# gcr_me14 register map
Registers are access not given, no defined reset value unless marked. A register's access mark holds for its fields unless they carry their own. Offsets are from the block's base; lines under a group give offsets from that group; [hi:lo] are bit positions; {n}, {i} and the like mark numbered series; 'fields as' and 'values as' point back to an identical list; <NAME> marks a mode.

## Memory map
0x40000000 GCR size 0x400 — Global Control Registers.

## GCR — Global Control Registers.
Base 0x40000000
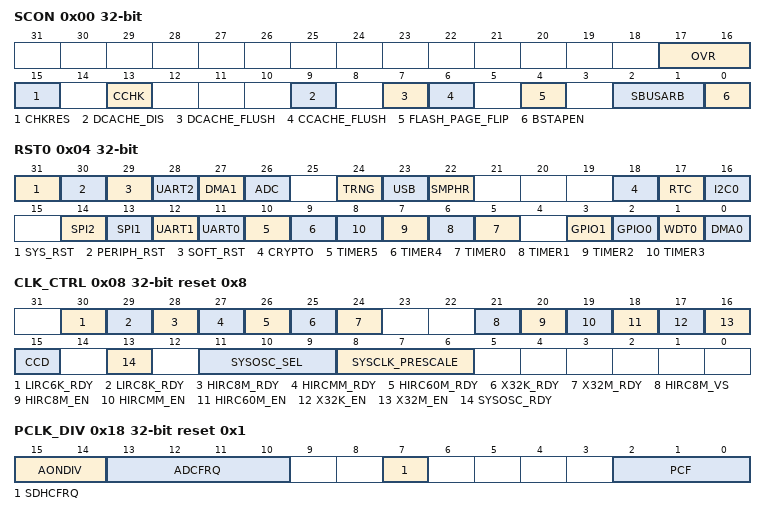
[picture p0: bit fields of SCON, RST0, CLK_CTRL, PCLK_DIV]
0x00 SCON — System Control.
  [17:16] OVR — Operating Voltage Range. Setting these bits according to the VCore voltage allows the on-chip Random-Access memories to operate in their optimal timing range.
    0=0_9V (0.9V +/- 10%); 1=1_0V (1.0V +/- 10%); 2=1_1V (1.1V +/- 10%)
  [15] CHKRES — ROM Checksum Result. This bit is only valid when CHKRD=1.
    0=pass (ROM Checksum Correct.); 1=fail (ROM Checksum Fail.)
  [13] CCHK — Compute ROM Checksum. This bit is self-cleared when calculation is completed. Once set, software clearing this bit is ignored and the bit will remain set until the operation is completed.
    0=complete (No operation/complete.); 1=Start operation
  [9] DCACHE_DIS — Data Cache Disable. The system cache(s) will be completely disabled when this bit is set.
    0=en (Is enabled.); 1=dis (Is Disabled.)
  [7] DCACHE_FLUSH — Data Cache Flush. The system cache(s) will be flushed when this bit is set.
    0=Normal System Cache Operation; 1=flush (System Cache is flushed)
  [6] CCACHE_FLUSH — Code Cache Flush. This bit is used to flush the code caches and the instruction buffer of the Cortex-M4.
    0=Normal Code Cache Operation; 1=flush (Code Caches and CPU instruction buffer are flushed)
  [4] FLASH_PAGE_FLIP — Flips the Flash bottom and top halves. (Depending on the total flash size, each half is either 256K or 512K). Initiating a flash page flip will cause a flush of both the data buffer on the DCODE bus and the internal instruction buffer.
    0=normal (Physical layout matches logical layout.); 1=swapped (Bottom half mapped to logical top half and vice versa.)
  [2:1] SBUSARB — System bus abritration scheme. These bits are used to select between Fixed-burst abritration and Round-Robin scheme. The Round-Robin scheme is selected by default. These bits are reset by the system reset.
    0=fix (Fixed Burst abritration.); 1=Round-robin scheme
  [0] BSTAPEN — Boundary Scan TAP enable. When enabled, the JTAG port is connected to the Boundary Scan TAP. Otherwise, the port is connected to the ARM ICE function. This bit is reset by the POR. Reset value and access depend on the part number.
    0=dis (Boundary Scan TAP port disabled.); 1=en (Boundary Scan TAP port enabled.)
0x04 RST0 — Reset.
  [31] SYS_RST — System Reset. Setting this bit to 1 resets the CPU core and all peripherals, including the watchdog timer.
  [30] PERIPH_RST — Peripheral Reset. Setting this bit to 1 resets all peripherals. The CPU core, the watchdog timer, and all GPIO pins are unaffected by this reset.
  [29] SOFT_RST — Soft Reset. Setting this bit to 1 resets everything except the CPU and the watchdog timer.
  [28] UART2 — UART2 Reset. Setting this bit to 1 resets all UART 2 blocks.
  [27] DMA1 — DMA 1 Reset.
  [26] ADC — Analog to Digital Reset.
  [24] TRNG — TRNG Reset.
  [23] USB — USB Reset. Setting this bit resets both USB blocks.
  [22] SMPHR — SMPHR Reset. Setting this bit to 1 resets the SMPHR block.
  [18] CRYPTO — Cryptographic Reset. Setting this bit to 1 resets the AES block, the SHA block and the DES block.
  [17] RTC — Real Time Clock Reset.
  [16] I2C0 — I2C0 Reset.
  [14] SPI2 — SPI2 Reset. Setting this bit to 1 resets all SPI 2 blocks.
  [13] SPI1 — SPI1 Reset. Setting this bit to 1 resets all SPI 1 blocks.
  [12] UART1 — UART1 Reset. Setting this bit to 1 resets all UART 1 blocks.
  [11] UART0 — UART0 Reset. Setting this bit to 1 resets all UART 0 blocks.
  [10] TIMER5 — Timer3 Reset. Setting this bit to 1 resets Timer 5 blocks.
  [9] TIMER4 — Timer3 Reset. Setting this bit to 1 resets Timer 4 blocks.
  [n+5] TIMER{n} (n=0..3) — Timer{n} Reset. Setting this bit to 1 resets Timer {n} blocks.
  [3] GPIO1 — GPIO1 Reset. Setting this bit to 1 resets GPIO1 pins to their default states.
  [2] GPIO0 — GPIO0 Reset. Setting this bit to 1 resets GPIO0 pins to their default states.
  [1] WDT0 — Watchdog Timer Reset.
  [0] DMA0 — DMA Reset.
    0=reset_done (Reset complete.); 1=busy (Starts Reset or indicates reset in progress.)
0x08 CLK_CTRL reset 0x8 — Clock Control.
  [30] LIRC6K_RDY ro — 6kHz Low Frequency Reference Clock Ready.
    0=not (Is not Ready.); 1=ready (Is Ready.)
  [29] LIRC8K_RDY ro — 8kHz Low Frequency Reference Clock Ready.
    0=not (Is not Ready.); 1=ready (Is Ready.)
  [28] HIRC8M_RDY ro — 8MHz HIRC Ready.
    0=not (Is not Ready.); 1=ready (Is Ready.)
  [27] HIRCMM_RDY ro — 96MHz HIRC Ready.
    0=not (Is not Ready.); 1=ready (Is Ready.)
  [26] HIRC60M_RDY ro — 60MHz HIRC Ready.
    0=not (Is not Ready.); 1=ready (Is Ready.)
  [25] X32K_RDY ro — 32kHz Crystal Oscillator Ready
    0=not (Is not Ready.); 1=ready (Is Ready.)
  [24] X32M_RDY ro — 32MHz Crystal Oscillator Ready
    0=not (Is not Ready.); 1=ready (Is Ready.)
  [21] HIRC8M_VS — 8MHz High Frequency Internal Reference Clock Voltage Select. This register bit is used to select the power supply to the HIRC8M.
    0=VCore Supply; 1=1V (Dedicated 1v regulated supply.)
  [20] HIRC8M_EN — 8MHz High Frequency Internal Reference Clock Enable.
    0=dis (Is Disabled.); 1=en (Is Enabled.)
  [19] HIRCMM_EN — 96MHz High Frequency Internal Reference Clock Enable.
    0=dis (Is Disabled.); 1=en (Is Enabled.)
  [18] HIRC60M_EN — 60MHz High Frequency Internal Reference Clock Enable.
    0=dis (Is Disabled.); 1=en (Is Enabled.)
  [17] X32K_EN — 32kHz Crystal Oscillator Enable.
    0=dis (Is Disabled.); 1=en (Is Enabled.)
  [16] X32M_EN — 32MHz Crystal Oscillator Enable.
    0=dis (Is Disabled.); 1=en (Is Enabled.)
  [15] CCD ro — Cryptographic clock divider
    0=non_div (The cryptographic accelerator clock is running in non-divided mode.); 1=div (The cryptographic accelerator clock is running in divided mode.)
  [13] SYSOSC_RDY ro — Clock Ready. This read only bit reflects whether the currently selected system clock source is running.
    0=busy (Switchover to the new clock source (as selected by CLKSEL) has not yet occurred.); 1=ready (System clock running from CLKSEL clock source.)
  [11:9] SYSOSC_SEL — Clock Source Select. This 3 bit field selects the source for the system clock.
    0=HIRC (HIRC Clock); 2=XTAL32M (32MHz Crystal is used for the system clock.); 3=LIRC8 (8kHz LIRC is used for the system clock.); 4=HIRC96 (The internal 96 MHz oscillator is used for the system clock.); 5=HIRC8 (The internal 8 MHz oscillator is used for the system clock.); 6=XTAL32k (32kHz is used for the system clock.)
  [8:6] SYSCLK_PRESCALE — Prescaler Select. This 3 bit field sets the system operating frequency by controlling the prescaler that divides the output of the PLL0.
    0=div1 (Divide by 1.); 1=div2 (Divide by 2.); 2=div4 (Divide by 4.); 3=div8 (Divide by 8.); 4=div16 (Divide by 16.); 5=div32 (Divide by 32.); 6=div64 (Divide by 64.); 7=div128 (Divide by 128.)
0x0C PMR — Power Management.
  [20] XTALPB — 32MHz Bluetooth Oscillator Bypass.
  [17] HIRC8MPD — 8MHz power down. This bit selects 8MHz HIRC power state in DEEPSLEEP mode.
    0=active (Mode is Active.); 1=deepsleep (Powered down in DEEPSLEEP.)
  [16] HIRC96MPD — 96MHz power down. This bit selects 96MHz HIRC power state in DEEPSLEEP mode.
    values as HIRC8MPD
  [15] HIRCPD — HIRC Power Down. This bit selects HIRC power state in DEEPSLEEP mode.
    values as HIRC8MPD
  [8] SDMAWKEN — SDMA Wake Up Enable. This bit enables SDMA IRQ activity as wakeup source.
    0=dis (Wake Up Disable.); 1=en (Wake Up Enable.)
  [8] compwken — COMPARATOR Input Wake Up Enable. This bit enables COMP IRQ activity as wakeup source.
    0=dis (Wake Up Disable.); 1=en (Wake Up Enable.)
  [7] WUTWKEN — WUT Wake Up Enable. This bit enables WUT IRQ as wakeup source.
    0=dis (Wake Up Disable.); 1=en (Wake Up Enable.)
  [6] USBWKEN — USB Wake Up Enable. This bit enables USB activity as wakeup source.
    0=dis (Wake Up Disable.); 1=en (Wake Up Enable.)
  [5] RTCWKEN — RTC Alarm Wake Up Enable. This bit enables RTC alarm as wakeup source. If enabled, the desired RTC alarm must be configured via the RTC control registers.
    0=dis (Wake Up Disable.); 1=en (Wake Up Enable.)
  [4] GPIOWKEN — GPIO Wake Up Enable. This bit enables all GPIO pins as potential wakeup sources. Any GPIO configured for wakeup is capable of causing an exit from IDLE or STANDBY modes when this bit is set.
    0=dis (Wake Up Disable.); 1=en (Wake Up Enable.)
  [2:0] MODE — Operating Mode. This two bit field selects the current operating mode for the device. Note that code execution only occurs during ACTIVE mode.
    0=Active Mode; 2=DeepSleep Mode; 3=Shutdown Mode; 4=Backup Mode
0x18 PCLK_DIV reset 0x1 — Peripheral Clock Divider.
  [15:14] AONDIV — Always-ON(AON) domain CLock Divider. These bits define the AON domain clock divider.
    0=div_4 (PCLK divide by 4.); 1=div_8 (PCLK divide by 8.); 2=div_16 (PCLK divide by 16.); 3=div_32 (PCLK divide by 32.)
  [13:10] ADCFRQ — ADC clock Frequency. These bits define the ADC clock frequency. FADC = FPCLK/(ADCFRQ).
  [7] SDHCFRQ — SDHC Clock Frequency. This bits defines the clock frequency of SDHC.
    0=48MHz; 1=24MHz
  [2:0] PCF — These bits determine the clock frequency for the UART, I2C and Key Pad peripherals. These peripherals have an adaptive clock generator that dynamically adjusts the peripheral frequency based on the main system bus frequency. These bits are dynamically updated when the PLL0 is selected as the system clock source and are set by hardware. These bits determine the clock frequency for the UART, I2C and Key Pad peripherals. These peripherals have an adaptive clock generator that dynamically adjusts the peripheral frequency based on the main system bus frequency. These bits are dynamically updated when the PLL0 is selected as the system clock source and are set by hardware.
    2=96MHz; 3=48MHz; 4=24MHz; 5=12MHz; 6=6MHz; 7=3MHz
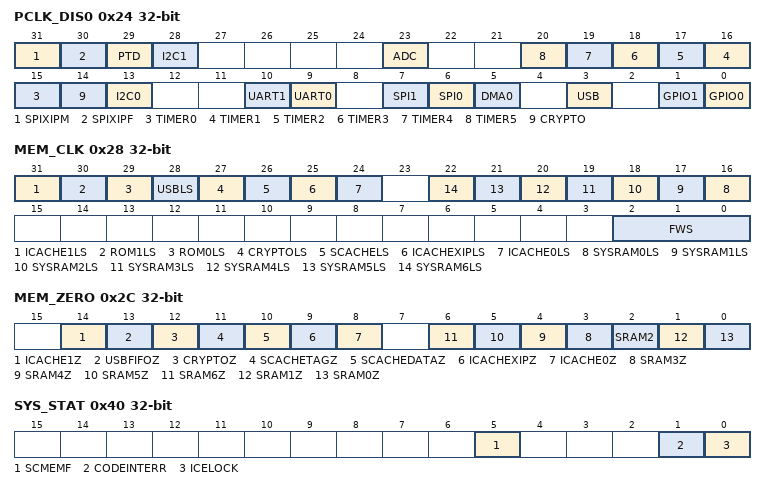
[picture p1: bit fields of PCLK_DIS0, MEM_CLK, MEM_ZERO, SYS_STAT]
0x24 PCLK_DIS0 — Peripheral Clock Disable.
  [31] SPIXIPM — SPI XiP Master Controller Disable.
  [30] SPIXIPF — SPI XiP Disable.
  [29] PTD — PT Clock Disable.
  [28] I2C1 — I2C 1 Disable.
  [23] ADC — ADC Disable.
  [n+15] TIMER{n} (n=0..5) — Timer {n} Disable.
  [14] CRYPTO — Crypto Disable.
  [13] I2C0 — I2C 0 Disable.
  [10] UART1 — UART 1 Disable.
  [9] UART0 — UART 0 Disable.
  [7] SPI1 — SPI 2 Disable.
  [6] SPI0 — SPI 1 Disable.
  [5] DMA0 — DMA Disable.
  [3] USB — USB Disable.
  [1] GPIO1 — GPIO1 Disable.
  [0] GPIO0 — GPIO0 Disable.
    0=en (enable it.); 1=dis (disable it.)
0x28 MEM_CLK — Memory Clock Control Register.
  [31] ICACHE1LS — ICache RAM Light Sleep Mode.
    0=active (RAM is active.); 1=light_sleep (RAM is in Light Sleep mode.)
  [30] ROM1LS — ROM1 Light Sleep Mode.
    values as ICACHE1LS
  [29] ROM0LS — ROM Light Sleep Mode.
    values as ICACHE1LS
  [28] USBLS — USB FIFO Light Sleep Mode.
    values as ICACHE1LS
  [27] CRYPTOLS — CRYPTO RAM Light Sleep Mode.
    values as ICACHE1LS
  [26] SCACHELS — SysCache RAM Light Sleep Mode.
    values as ICACHE1LS
  [25] ICACHEXIPLS — ICACHE-XIP RAM Light Sleep Mode.
    values as ICACHE1LS
  [24] ICACHE0LS — ICache RAM Light Sleep Mode.
    values as ICACHE1LS
  [n+16] SYSRAM{n}LS (n=0..6) — System RAM {n} Light Sleep Mode.
    values as ICACHE1LS
  [2:0] FWS — Flash Wait State. These bits define the number of wait-state cycles per Flash data read access. Minimum wait state is 2.
0x2C MEM_ZERO — Memory Zeroize Control.
  [all] fields
    0=nop (No operation/complete.); 1=Start operation
  [14] ICACHE1Z — Instruction Cache.
  [13] USBFIFOZ — USB FIFO Zeroizatoin.
  [12] CRYPTOZ — Crypto (MAA) Memory.
  [11] SCACHETAGZ — System Cache Tag Zeroization.
  [10] SCACHEDATAZ — System Cache Data Ram Zeroization.
  [9] ICACHEXIPZ — Instruction Cache XIP Data and Tag Ram zeroizatoin.
  [8] ICACHE0Z — Instruction Cache.
  [n] SRAM{n}Z (n=3..6) — System RAM Block {n}.
  [2] SRAM2 — System RAM Block 2.
  [1] SRAM1Z — System RAM Block 1.
  [0] SRAM0Z — System RAM Block 0.
0x34 SCCK reset 0x1414 — Smart Card Clock Control.
0x38 MPRI0 reset 0x1414 — Master Priority Control Register 0.
0x3C MPRI1 reset 0x1414 — Mater Priority Control Register 1.
0x40 SYS_STAT — System Status Register.
  [5] SCMEMF — System Cache Memory Fault Flag. This bit indicates a memory fault has occured in the System Cache while receiving data from the Hyperbus Interface.
    0=Normal Operating Condition; 1=Memory Fault
  [1] CODEINTERR — Code Integrity Error Flag. This bit indicates a code integrity error has occured in XiP interface.
    0=Normal Operating Condition; 1=Code Integrity Error
  [0] ICELOCK — ARM ICE Lock Status.
    0=unlocked (ICE is unlocked.); 1=locked (ICE is locked.)
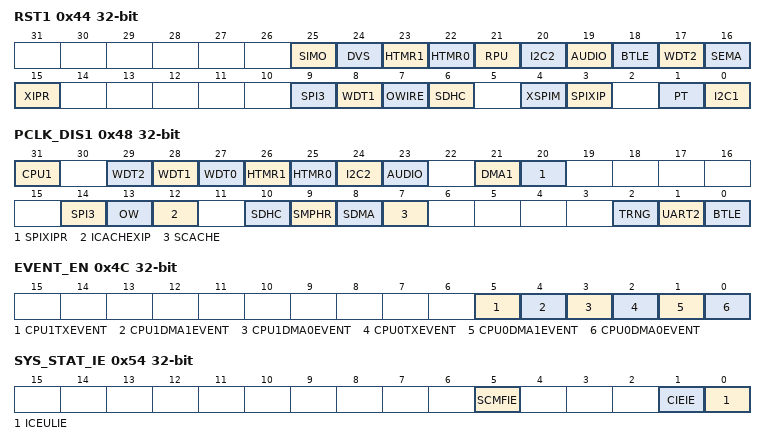
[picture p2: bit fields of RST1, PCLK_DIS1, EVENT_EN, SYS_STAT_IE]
0x44 RST1 — Reset 1.
  [all] fields
    on read: 0=reset_done (Reset complete.); 1=busy (Starts reset or indicates reset in progress.)
  [25] SIMO — SIMO Reset.
  [24] DVS — DVS Reset.
  [23] HTMR1 — HTMR1 Reset.
  [22] HTMR0 — HTMR0 Reset.
  [21] RPU — RPU Reset.
  [20] I2C2 — I2C2 Reset.
  [19] AUDIO — AUDIO Reset.
  [18] BTLE — BTLE Reset.
  [17] WDT2 — WDT2 Reset.
  [16] SEMA — SMPHR Reset.
  [15] XIPR — SPIXMEM Reset.
  [9] SPI3 — SPI0 Reset.
  [8] WDT1 — WDT1 Reset.
  [7] OWIRE — OWIRE Reset.
  [6] SDHC — SDHC/SDIO Reset.
  [4] XSPIM — GSPI XiP Master Controller Reset.
  [3] SPIXIP — SPI XiP Master Reset.
  [1] PT — PT Reset.
  [0] I2C1 — I2C1 Reset.
0x48 PCLK_DIS1 — Peripheral Clock Disable.
  [31] CPU1 — CPU1 Clock Disable
  [29] WDT2 — WDT2 Clock Disable
  [28] WDT1 — WDT1 Clock Disable
  [27] WDT0 — WDT0 Clock Disable
  [26] HTMR1 — HTMR 1 Clock Disable
  [25] HTMR0 — HTMR 0 Clock Disable
  [24] I2C2 — I2C 2 Clock Disable
  [23] AUDIO — AUDIO Clock Disable
  [21] DMA1 — DMA1 Clock Disable
  [20] SPIXIPR — SPI-XIP Data Clock Disable
  [14] SPI3 — SPI0 Clock Disable.
  [13] OW — One-Wire Clock Disable.
  [12] ICACHEXIP — ICache XIP Clock Disable.
  [10] SDHC — SDHC/SDIO Clock Disable.
  [9] SMPHR — Semaphore Clock Disable.
  [8] SDMA — SDMA Clock Disable.
  [7] SCACHE — System Cache Clock Disable.
  [2] TRNG — TRNG Disable.
  [1] UART2 — UART2 Disable.
    0=en (Enable.); 1=dis (Disable.)
  [0] BTLE — BTLE Disable.
    0=en (Enable.); 1=dis (Disable.)
0x4C EVENT_EN — Event Enable Register.
  [5] CPU1TXEVENT — Enable TXEV pin event. When this bit is set, TXEV event from the CPU is output to GPIO[25].
  [4] CPU1DMA1EVENT — Enable RXEV pin event. When this bit is set, a logic high of GPIO0[24] will cause an RXEV event to wake the CPU from WFE sleep mode.
  [3] CPU1DMA0EVENT — Enable DMA event. When this bit is set, a DMA event will cause an RXEV event to wake the CPU from WFE sleep mode.
  [2] CPU0TXEVENT — Enable TXEV pin event. When this bit is set, TXEV event from the CPU is output to GPIO[25].
  [1] CPU0DMA1EVENT — Enable RXEV pin event. When this bit is set, a logic high of GPIO0[24] will cause an RXEV event to wake the CPU from WFE sleep mode.
  [0] CPU0DMA0EVENT — Enable DMA event. When this bit is set, a DMA event will cause an RXEV event to wake the CPU from WFE sleep mode.
0x50 REVISION ro
  [15:0] REVISION — Manufacturer Chip Revision.
0x54 SYS_STAT_IE — System Status Interrupt Enable Register.
  [all] fields
    0=dis (disabled.); 1=en (enabled.)
  [5] SCMFIE — System Cache Memory Fault Interrupt Enable.
  [1] CIEIE — Code Integrity Error Interrupt Enable.
  [0] ICEULIE — ARM ICE Unlock Interrupt Enable.
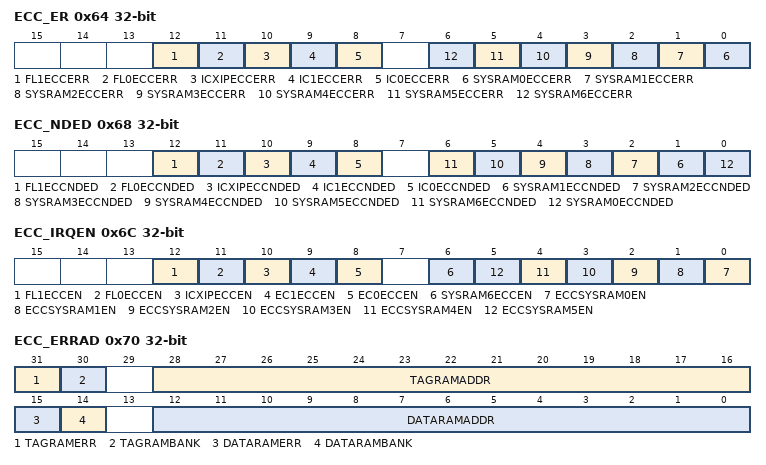
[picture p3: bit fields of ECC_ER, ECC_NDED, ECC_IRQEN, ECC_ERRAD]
0x64 ECC_ER — ECC Error Register
  [12] FL1ECCERR — ECC Flash1 Error Flag. Write 1 to clear.
  [11] FL0ECCERR — ECC Flash0 Error Flag. Write 1 to clear.
  [10] ICXIPECCERR — ECC IcacheXIP Error Flag. Write 1 to clear.
  [9] IC1ECCERR — ECC Icache1 Error Flag. Write 1 to clear.
  [8] IC0ECCERR — ECC Icache0 Error Flag. Write 1 to clear.
  [n] SYSRAM{n}ECCERR (n=0..6) — ECC System RAM{n} Error Flag. Write 1 to clear.
0x68 ECC_NDED — ECC Not Double Error Detect Register
  [12] FL1ECCNDED — ECC Flash1 Not Double Error Detect. Write 1 to clear.
  [11] FL0ECCNDED — ECC Flash0 Not Double Error Detect. Write 1 to clear.
  [10] ICXIPECCNDED — ECC IcacheXIP Not Double Error Detect. Write 1 to clear.
  [9] IC1ECCNDED — ECC Icache1 Not Double Error Detect. Write 1 to clear.
  [8] IC0ECCNDED — ECC Icache0 Not Double Error Detect. Write 1 to clear.
  [n] SYSRAM{n}ECCNDED (n=1..6) — ECC System RAM{n} Not Double Error Detect. Write 1 to clear.
  [0] SYSRAM0ECCNDED — ECC System RAM0 Error Flag. Write 1 to clear.
0x6C ECC_IRQEN — ECC IRQ Enable Register
  [12] FL1ECCEN — ECC Flash1 NError Interrup Enable
  [11] FL0ECCEN — ECC Flash0 NError Interrup Enable
  [10] ICXIPECCEN — ECC IcacheXIP Error Interrup Enable
  [9] EC1ECCEN — ECC Icache1 Error Interrup Enable
  [8] EC0ECCEN — ECC Icache0 Error Interrup Enable
  [6] SYSRAM6ECCEN — ECC System RAM6 Error Interrup Enable
  [n] ECCSYSRAM{n}EN (n=0..5) — ECC System RAM{n} Error Interrup Enable
0x70 ECC_ERRAD — ECC Error Address Register
  [31] TAGRAMERR — ECC Error Address.Tag Ram Error.
  [30] TAGRAMBANK — ECC Error Address.Tag Ram Bank.
  [28:16] TAGRAMADDR — ECC Error Address.Tag Ram Address.
  [15] DATARAMERR — ECC Error Address.Data Ram Error.
  [14] DATARAMBANK — ECC Error Address.Data Error Bank.
  [12:0] DATARAMADDR — ECC Error Address.Data Ram Address.
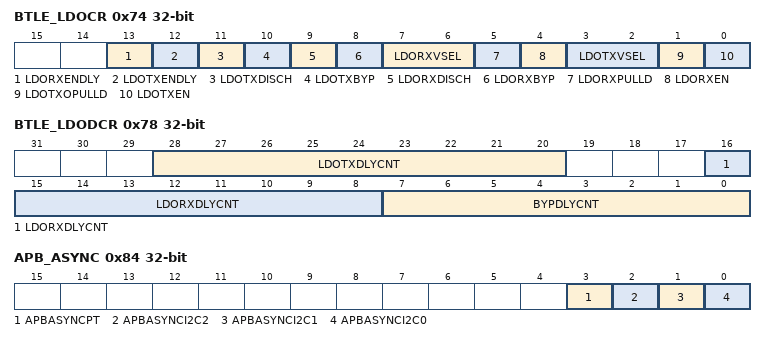
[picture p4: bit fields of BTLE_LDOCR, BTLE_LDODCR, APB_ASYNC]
0x74 BTLE_LDOCR — BTLE LDO Control Register
  [13] LDORXENDLY — LDOW Enable Delay Status
    0=dis (disabled.); 1=en (enabled.)
  [12] LDOTXENDLY — LDOWO Enable Delay Status
    0=dis (disabled.); 1=en (enabled.)
  [11] LDOTXDISCH — LDOWO Discharge
    0=dis (disabled.); 1=en (enabled.)
  [10] LDOTXBYP — LDOWO Bypass Enable
    0=dis (disabled.); 1=en (enabled.)
  [9] LDORXDISCH — LDOW Discharge
    0=dis (disabled.); 1=en (enabled.)
  [8] LDORXBYP — LDO Bypass Enable
    0=dis (disabled.); 1=en (enabled.)
  [7:6] LDORXVSEL — LDOW Voltage Setting
    0=0_7 (0.7V); 1=0.85V; 2=0_9 (0.9V); 3=1.1V
  [5] LDORXPULLD — LDOW PULL Disable
    0=en (enabled.); 1=dis (disabled.)
  [4] LDORXEN — LDOW Enable
    0=dis (disabled.); 1=en (enabled.)
  [3:2] LDOTXVSEL — LDOWO Voltage Setting
    0=0_7 (0.7V); 1=0.85V; 2=0_9 (0.9V); 3=1.1V
  [1] LDOTXOPULLD — LDOWO PULL Disable
    0=en (enabled.); 1=dis (disabled.)
  [0] LDOTXEN — LDOWO Enable
    0=dis (disabled.); 1=en (enabled.)
0x78 BTLE_LDODCR — BTLE LDO Delay Register
  [28:20] LDOTXDLYCNT — LDOWO Delay Count. Count delay base on PCLK/128.
  [16:8] LDORXDLYCNT — LDOW Delay Count. Count delay base on PCLK/128.
  [7:0] BYPDLYCNT — Bypass Delay Count. Count delay base on PCLK.
0x80 GPR0 — General Purpose Register 0
  [31:0] GPR0 — User-defined register RAM.
0x84 APB_ASYNC — APB Asynchronous Bridge Select Register
  [all] fields
    0=PCLK Source; 1=7mclk (7.37MHz Source)
  [3] APBASYNCPT — Feeds PT with either PCLK or 7.37MHz Clk
  [2] APBASYNCI2C2 — Feeds I2C2 with either PCLK or 7.37MHz Clk
  [1] APBASYNCI2C1 — Feeds I2C1 with either PCLK or 7.37MHz Clk
  [0] APBASYNCI2C0 — Feeds I2C0 with either PCLK or 7.37MHz Clk
